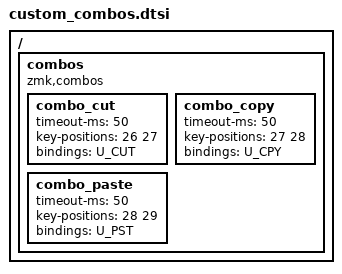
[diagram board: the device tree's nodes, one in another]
/ {
    combos {
        compatible = "zmk,combos";
        combo_cut {
            timeout-ms = <50>;
            key-positions = <26 27>;
            bindings = <U_CUT>;
        };
        combo_copy {
            timeout-ms = <50>;
            key-positions = <27 28>;
            bindings = <U_CPY>;
        };
        combo_paste {
            timeout-ms = <50>;
            key-positions = <28 29>;
            bindings = <U_PST>;
        };
    };
};
